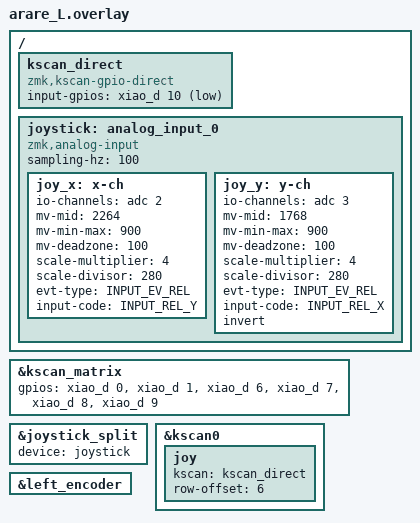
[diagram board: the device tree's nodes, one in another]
/* arare 左手（peripheral）
 * M0=D0 M1=D1 M2=D6 M3=D7 M4=D8 M5=D9 / EC12=D2,D3 / JOY_SW=D10
 * （実基板 arare_L.kicad_pcb の XIAO パッド→ネットと機械照合済み 2026-08-31）
 */

#include "arare.dtsi"

#include <zephyr/dt-bindings/input/input-event-codes.h>

/* 電池ドライバの差し替え（arare_saadc_fix.dtsi）は arare_tuning_L.dtsi 側で行う。
 * ジョイスティックを付けない構成では差し替えないため、arare Studio が構成に応じて出し分ける。 */

&kscan_matrix {
    gpios
        = <&xiao_d 0 GPIO_ACTIVE_HIGH>   /* M0 */
        , <&xiao_d 1 GPIO_ACTIVE_HIGH>   /* M1 */
        , <&xiao_d 6 GPIO_ACTIVE_HIGH>   /* M2 */
        , <&xiao_d 7 GPIO_ACTIVE_HIGH>   /* M3 */
        , <&xiao_d 8 GPIO_ACTIVE_HIGH>   /* M4 */
        , <&xiao_d 9 GPIO_ACTIVE_HIGH>   /* M5 */
        ;
};

/ {
    /* ジョイスティック押込（D10-GND直結）。デュアルFP時のChocスイッチも同じ線 */
    kscan_direct: kscan_direct {
        compatible = "zmk,kscan-gpio-direct";
        input-gpios = <&xiao_d 10 (GPIO_ACTIVE_LOW | GPIO_PULL_UP)>;
    };

    /* ジョイスティック NS40-T のアナログXY（2026-09-05）
     *   /L_JOY_X = XIAO pad5 = D4 = P0.04 = AIN2
     *   /L_JOY_Y = XIAO pad6 = D5 = P0.05 = AIN3
     *   （実基板 arare_L.kicad_pcb のネットと seeed_xiao_connector.dtsi で照合済み）
     *
     * ★★ 子ノードは io-channels のチャネル番号の昇順で並べること ★★
     *   ドライバは adc_read を1回だけ発行し、結果を as_buff[子ノードのindex] で読む。
     *   一方 SAADC はバッファへチャネル番号の昇順で詰める。
     *   よって AIN2 を先、AIN3 を後にしないと X と Y が入れ替わる。
     *
     * ★ report-on-change-only は絶対に付けないこと。
     *   付けると「倒し続けても最初の1回しか動かない」挙動になる。
     *
     * ★★ 実機の軸は想定から90°回っている（2026-09-22 実測）★★
     *   AIN2（/L_JOY_X と名付けた線）が「奥・手前」、AIN3（/L_JOY_Y）が「左・右」に振れる。
     *   子ノードの並びは上の理由で変えられないので、input-code を入れ替えて合わせる:
     *     joy_x（AIN2）→ REL_Y（奥=負・手前=正。そのままで向きも合う）
     *     joy_y（AIN3）→ REL_X（左=正・右=負で逆向きなので invert）
     *
     * 中点と振れ幅も実測値（~/arare/tools/dfu/joy_measure.py、ブランチ cal-L-joy のログ）:
     *   AIN2: 離すと 2228〜2285 mV（中央値 2264）。奥 −1284、手前 +1036（3.3V で頭打ち）
     *   AIN3: 離すと 1744〜1777 mV（中央値 1768）。左 +1334、右 −1330
     *   揺れは ±15 mV 程度。離すたびの戻り位置のずれが最大 ±40 mV ほどある。
     *   ※仮置きの 1650 のままだと AIN2 が常に +600 mV 倒れている扱いになり、
     *     触っていないのにジェスチャが1秒に十数回出続けた。
     *
     * これらはこの基板・この部品の事実なので overlay に置く。
     * arare Studio が生成する arare_tuning_L.dtsi は mv-deadzone しか出さないため、
     * そちらに置くと Studio で再生成した瞬間に消える。
     * invert も同じ理由でここに置く（DT の boolean は後から消せないが、向きは部品で決まる）。 */
    joystick: analog_input_0 {
        compatible = "zmk,analog-input";
        status = "okay";
        sampling-hz = <100>;

        joy_x: x-ch {                      /* 昇順1番目: AIN2 = 実機の「奥・手前」 */
            io-channels = <&adc 2>;
            mv-mid = <2264>;               /* 実測 */
            mv-min-max = <900>;            /* 手前側は +1036 で頭打ちなので、両側で届く値に揃える */
            mv-deadzone = <100>;           /* uint8_t 格納なので 255 以下。tuning 側で上書きされる */
            scale-multiplier = <4>;
            scale-divisor = <280>;         /* 1/70 と同比のまま分解能を上げてある */
            evt-type = <INPUT_EV_REL>;
            input-code = <INPUT_REL_Y>;    /* 90°回っているので Y へ */
        };

        joy_y: y-ch {                      /* 昇順2番目: AIN3 = 実機の「左・右」 */
            io-channels = <&adc 3>;
            mv-mid = <1768>;               /* 実測 */
            mv-min-max = <900>;
            mv-deadzone = <100>;
            scale-multiplier = <4>;
            scale-divisor = <280>;
            evt-type = <INPUT_EV_REL>;
            input-code = <INPUT_REL_X>;    /* 90°回っているので X へ */
            invert;                        /* 右に倒すと電圧が下がるため */
        };
    };
};

/* peripheral(左)側は device の指定が必須。
 * ここに input-processors を足す場合、state が NULL で渡るため
 * scaler は端数が捨てられ、behaviors 系は NULL 参照で落ちる。
 * 速度・加速は central(右) 側の &joystick_listener に置くこと。 */
&joystick_split {
    device = <&joystick>;
};

&kscan0 {
    joy {
        kscan = <&kscan_direct>;
        row-offset = <6>;
    };
};

&left_encoder {
    status = "okay";
};

/* 左エンコーダ・ジョイスティックの詳細設定は別ファイルに分離。
 * arare Studio の生成テキストで差し替える */
#include "arare_tuning_L.dtsi"
